# TC37XPD register map
Vendor: Infineon; Series: ATVMC; File version: 100
CPU: other r0p0, little endian, MPU, FPU, vendor SysTick, 4 interrupt priority bits
Registers are 32-bit, read-write, reset 0x0 unless marked. A register's access mark holds for its fields unless they carry their own. Offsets are from the block's base; [hi:lo] are bit positions; lines under a group give offsets from that group; {n}, {i} and the like mark numbered series.

## PMS (part 3 of 3)
Base 0xF0248000
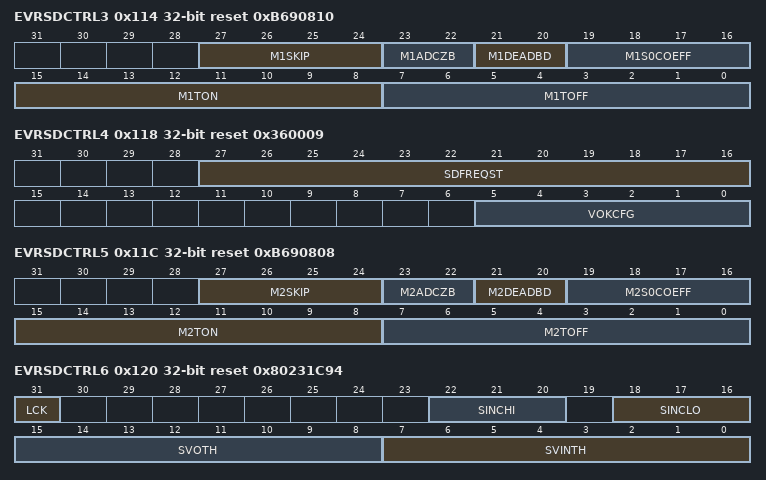
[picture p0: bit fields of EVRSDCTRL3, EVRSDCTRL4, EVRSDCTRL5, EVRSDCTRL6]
0x114 EVRSDCTRL3 reset 0xB690810 — EVRC SD Control Register 3 resetvalue={LVD Reset:0x0B690810,Cold PORST:0x0B690810,After SSW execution:0x0B690810}
  [27:24] M1SKIP — Skip Pulse Threshold m1skip thres i M1SKIP. This bitfield is disabled in LPM mode as PFM applied by control itself.
  [23:22] M1ADCZB — ADC Zero Bin m1fcfg adczb i M1ADCZB. This bitfield specifies the zero error bin during LP mode.
  [21:20] M1DEADBD — Dead Band m1s0 deadbd i M1DEADBD. This bitfield specifies the dead band to block the ADC ripple during LP mode.
  [19:16] M1S0COEFF — S0 coefficient m1s0 coeff i M1S0COEFF. This bitfield indicates the S0 coefficient during LP mode.
  [15:8] M1TON — Minimum On Time m1ton minton i M1TON. This bitfield configures the minimum on time within one period in 100MHz clock cycle periods during LP mode.
  [7:0] M1TOFF — Minimum Off Time m1toff mintof i M1TOFF. This bitfield configures the minimum off time within one period in 100MHz clock cycle periods during LP mode.
0x118 EVRSDCTRL4 reset 0x360009 — EVRC SD Control Register 4 resetvalue={LVD Reset:0x360009,Cold PORST:0x360009,After SSW execution:0x360009}
  [27:16] SDFREQST — Regulator Switching Frequency or Over sampling Factor m2osfl fact i m2osfh fact i SDFREQST. This bit field configures the EVRC regulator switching frequency during closed loop start up.The switching frequency is equal to 100 160 MHz SDFREQ value. SDFREQ represents the corresponding over sampling factor.
  [5:0] VOKCFG — Voltage OK Circuit Configuration vokcfg config i VOKCFG. t.b.d.
0x11C EVRSDCTRL5 reset 0xB690808 — EVRC SD Control Register 5 resetvalue={LVD Reset:0x0B690808,Cold PORST:0x0B690808,After SSW execution:0x0B690808}
  [27:24] M2SKIP — Skip Pulse Threshold m2skip thres i M2SKIP. This bitfield specifies the threshold to detect a skip pulse condition during closed loop operation. N channel MOSFET .
  [23:22] M2ADCZB — ADC Zero Bin m2fcfg adczb i M2ADCZB. This bitfield specifies the zero error bin during closed loop operation.
  [21:20] M2DEADBD — Dead Band m2s0 deadbd i M2DEADBD. This bitfield specifies the dead band to block the ADC ripple during closed loop operation.
  [19:16] M2S0COEFF — S0 coefficient m2s0 coeff i M2S0COEFF. This bitfield indicates the S0 coefficient during closed loop operation.
  [15:8] M2TON — Minimum On Time m2ton minton i M2TON. This bitfield configures the minimum on time within one period in 100MHz clock cycle periods during closed loop operation.
  [7:0] M2TOFF — Minimum Off Time m2toff mintof i M2TOFF. This bitfield configures the minimum off time within one period in 100MHz clock cycle periods during closed loop operation.
0x120 EVRSDCTRL6 access per field reset 0x80231C94 — EVRC SD Control Register 6 resetvalue={LVD Reset:0x080231C94,Cold PORST:0x080231C94,After SSW execution:0x080231C94}
  [31] LCK ro — Lock Status LCK. This bit indicates if the register can be updated with a new value or if the register is locked and a write action from the bus side has no effect. When EVRSDCTRL0.UP bit is set to 1 register is locked for shadow register update and LCK bit is set to 1. Once shadow register update is done the lock is released and LCK bit is set to 0.
  [22:20] SINCHI rw — Increment for high input voltage. sinc sinchi i SINCHI. This bitfield specifies the increment of the on time during open loop ramp up during startup. If Vin is below the threshold SVINTH SINCLO is taken as ramp up increment. if Vin is equal or above the threshold SVINTH SINCHI is taken as ramp up increment
  [18:16] SINCLO rw — Increment for low input voltage. sinc sinclo i SINCLO. This bitfield specifies the increment of the on time during open loop ramp up during startup. If Vin is below the threshold SVINTH SINCLO is taken as ramp up increment. if Vin is equal or above the threshold SVINTH SINCHI is taken as ramp up increment
  [15:8] SVOTH rw — Vout threshold to switch from open loop start up to closed loop mode. svoth thres i SVOTH. This bit field specifies the threshold to decide when to switch from open loop mode to closed loop mode during startup. If Vout is below the threshold open loop ramp up is executed. if Vout is equal or above the threshold closed loop PWM in start up configuration is executed. The threshold is compared to the low pass filtered FB ADC counter value without offset. The switch happens only in one direction during startup and the system does not switch back into start up mode even if threshold is crossed in other direction.
  [7:0] SVINTH rw — Vin threshold to switch between SINCLO or SINCHI. svinth thres i SVINTH. This bit field specifies the threshold to decide on the ramp up increment during startup. If Vin is below the threshold SINCLO is taken as ramp up increment else if Vin is equal or above the threshold SINCHI is taken as ramp up increment.The threshold is compared to the FF ADC counter value without offset.
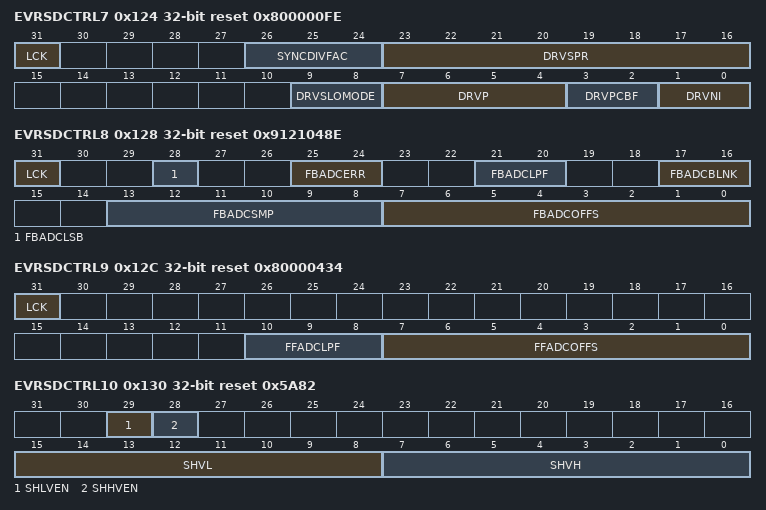
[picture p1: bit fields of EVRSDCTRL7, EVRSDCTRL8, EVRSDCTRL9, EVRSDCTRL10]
0x124 EVRSDCTRL7 access per field reset 0x800000FE — EVRC SD Control Register 7 resetvalue={LVD Reset:0x0800000FE,Cold PORST:0x0800000FE,After SSW execution:0x0800000FE}
  [31] LCK ro — Lock Status LCK. This bit indicates if the register can be updated with a new value or if the register is locked and a write action from the bus side has no effect. When EVRSDCTRL0.UP bit is set to 1 register is locked for shadow register update and LCK bit is set to 1. Once shadow register update is done the lock is released and LCK bit is set to 0.
  [26:24] SYNCDIVFAC rw — Switching frequency division factor for external synchronisation synco divfac i SYNCDIVFAC. This bit field defines the divider factor for the SMPS switching output to generate DCDCSYNCO output to synchronize external regulator to the internal EVRC regulator. The sigal is routed to pin if enabled via PMSWCR5.DCDCSYNCO bit. All other combinations are reserved.
  [23:16] DRVSPR rw — Spare bits drvspr x i DRVSPR
  [9:8] DRVSLOMODE rw — Switching Configuration drvslo mode i DRVSLOMODE. This bitfield configure the type of switching.
  [7:4] DRVP rw — P Driver Current drvp strgth i DRVP. Base drive current of the P channel MOSFET when driven with 3.3V 160 160 5V.
  [3:2] DRVPCBF rw — P Driver Current Boost Factor drvp strgth i DRVPCBF. Adjustable boost factor for the P driver current
  [1:0] DRVNI rw — Selection of N driver current DRVNI. Adjustable driver strength of the N driver current
0x128 EVRSDCTRL8 access per field reset 0x9121048E — EVRC SD Control Register 8 resetvalue={LVD Reset:0x09121048E,Cold PORST:0x09121048E,After SSW execution:0x09121048E}
  [31] LCK ro — Lock Status LCK. This bit indicates if the register can be updated with a new value or if the register is locked and a write action from the bus side has no effect. When EVRSDCTRL0.UP bit is set to 1 register is locked for shadow register update and LCK bit is set to 1. Once shadow register update is done the lock is released and LCK bit is set to 0.
  [28] FBADCLSB rw — FB ADC LSB for Error Computation fbadc3 lsb i FBADCLSB. This bitfield configures the LSB of the feedback ADC counter value used for the error computation.
  [25:24] FBADCERR rw — FB ADC Error LPF Coefficient fbadc3 lpferr i FBADCERR. This bitfield configures the coefficient of the Low Pass Filter of the output voltage error signal of the feedback ADC.
  [21:20] FBADCLPF rw — FB ADC Counter LPF Coefficient fbadc0 lpfcnt i FBADCLPF. This bit field configures the coefficient of the Low Pass Filter of the feedback ADC counter value measuring the core voltage. y 160 k 160 160 160 y 160 k 1 160 160 1 a 160 160 160 160 x 160 k 160 160 a 160 y 160 k is filter output x 160 k is ADC output a 160 160 1 160 160 2 160 160 LPF .If LPF 160 160 0 the filter output is the same as ADC output.
  [17:16] FBADCBLNK rw — FB ADC Blanked Samples Number fbadc0 blank i FBADCBLNK. This bitfield configures the number of feedback ADC samples that are blanked in case of a transition of the PWM drive output to minimise switching noise influence.
  [13:8] FBADCSMP rw — FB ADC Sampling period fbadc1 smpthr i FBADCSMP. This bitfield configures the sampling period in 100 MHz clock cycles for the feedback ADC measuring the core voltage.
  [7:0] FBADCOFFS rw — Feedback Converted Counter Value Offset fbadc2 offset i FBADCOFFS. This bitfield configures the offset of the converted counter value of the feedback ADC measuring the core voltage.
0x12C EVRSDCTRL9 access per field reset 0x80000434 — EVRC SD Control Register 9 resetvalue={LVD Reset:0x080000434,Cold PORST:0x080000434,After SSW execution:0x080000434}
  [31] LCK ro — Lock Status LCK. This bit indicates if the register can be updated with a new value or if the register is locked and a write action from the bus side has no effect. When EVRSDCTRL0.UP bit is set to 1 register is locked for shadow register update and LCK bit is set to 1. Once shadow register update is done the lock is released and LCK bit is set to 0.
  [10:8] FFADCLPF rw — FF ADC Counter LPF Coefficient ffadc0 lpfcnt i FFADCLPF. This bit field configures the coefficient of the Low Pass Filter of the feed forward ADC counter value measuring the input VEXT voltage. y 160 k 160 160 160 y 160 k 1 160 160 1 a 160 160 160 160 x 160 k 160 160 a 160 y 160 k is filter output x 160 k is ADC output a 160 160 1 160 160 2 160 160 LPF .If LPF 160 160 0 the filter output is the same as ADC output.
  [7:0] FFADCOFFS rw — Feed Forward Converted Counter Value Offset ffadc1 offset i FFADCOFFS. This bit field configures the offset of the converted counter value of the feed forward ADC measuring the input VEXT voltage.
0x130 EVRSDCTRL10 reset 0x5A82 — EVRC SD Control Register 10 resetvalue={LVD Reset:0x5A82,Cold PORST:0x5A82,After SSW execution:0x5A82}
  [29] SHLVEN — Short to Low Detection Enable shrtl0 shlven i SHLVEN
  [28] SHHVEN — Short to High Detection Enable shrth0 shhven i SHHVEN
  [15:8] SHVL — Short to Low Voltage Threshold shrtl1 shvl i SHVL. Low Voltage Threshold SDVOUTSEL 160 160 SHVL 160 x 160 5 160 mV . EVRC short to ground alarm has the nominal values of SHVL of 0.8V and tCSHLV of 3ms.
  [7:0] SHVH — Short to High Voltage Threshold shrth1 shvh i SHVH. High Voltage Threshold SDVOUTSEL 160 160 SHVH 160 x 160 5 160 mV . EVRC short to supply alarm has the nominal values of SHVH of 1.9V and tCSHHV of 3ms.
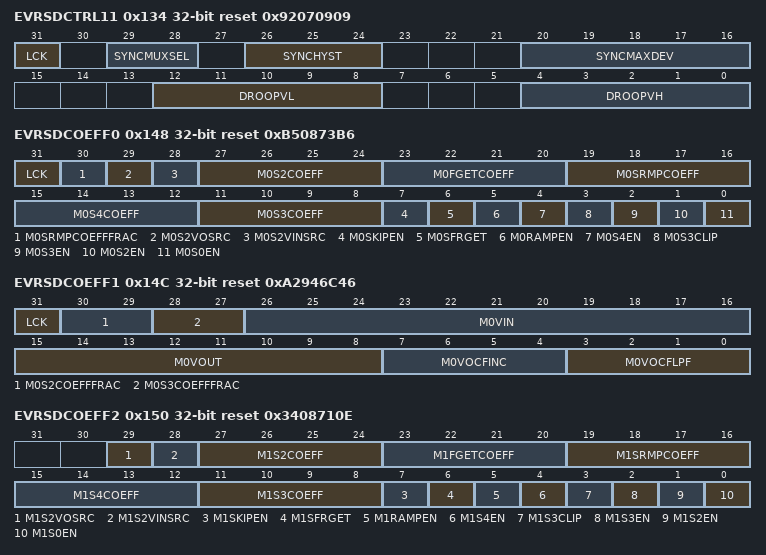
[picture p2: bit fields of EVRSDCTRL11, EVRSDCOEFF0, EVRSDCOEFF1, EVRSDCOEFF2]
0x134 EVRSDCTRL11 access per field reset 0x92070909 — EVRC SD Control Register 11 resetvalue={LVD Reset:0x092070909,Cold PORST:0x092070909,After SSW execution:0x092070909}
  [31] LCK ro — Lock Status LCK. This bit indicates if the register can be updated with a new value or if the register is locked and a write action from the bus side has no effect. When EVRSDCTRL0.UP bit is set to 1 register is locked for shadow register update and LCK bit is set to 1. Once shadow register update is done the lock is released and LCK bit is set to 0.
  [29:28] SYNCMUXSEL rw — Synchronisation Input Multiplexer SYNCMUXSEL. This bitfield selects synchronisation input either from CCU6 or GTM inputs to be forwarded to EVRC SMPS regulator.
  [26:24] SYNCHYST rw — Lock Unlock Hysteresis Window synci0 hyst i SYNCHYST. This bitfield defines the hysteresis window for synchronization locking and unlocking. For locking EVRSDCTRL11.SYNCHYST has to be chosen to be lower or equal to the value of EVRSDCTRL11.SYNCMAXDEV and unequal to zero. The limit is applied to the period counter running at 100 MHz. Upper unlock condition SDFREQ SYNCMAXDEV Upper lock condition SDFREQ SYNCMAXDEV SYNCHYST Lower unlock condition SDFREQ SYNCMAXDEV Lower lock condition SDFREQ SYNCMAXDEV SYNCHYST SYNCHYST round d 160 f HYST SDFREQ 177 SYNCMAXDEV 2 d 160 f HYST SDFREQ 177 SYNCMAXDEV 100 MHz
  [20:16] SYNCMAXDEV rw — Maximum Deviation of the Synchronization Input Frequency synci1 maxdev i SYNCMAXDEV. This bitfield defines the maximum allowed frequency deviation of the synchronization input signal frequency from the programmed nominal DCDC switching frequency EVRSDCTRL0.SDFREQ . For locking EVRSDCTRL11.SYNCMAXDEV has to be chosen to be greater or equal to the value of EVRSDCTRL11.SYNCHYST and unequal to zero. Violation of limit leads to loss of synchronization.The frequency window is defined as follows d 160 f MAXDEV 160 100 MHz 2 SYNCMAXDEV SDFREQ 2 SYNCMAXDEV 2 SYNCMAXDEV 160 round 100 MHz d 160 f MAXDEV sqrt 100 MHz d 160 f MAXDEV 2 SDFREQ 2
  [12:8] DROOPVL rw — Low VDD Limit for Droop request droopvl thres i DROOPVL. This bitfield defines the VDD low voltage limit below which a negative droop request on VDD voltage shall be ignored. VDD Droop Low Limit 712.5 mV LSB SDVOUTSEL SDVOUTTRIM DROOPVL LSB 5 mV
  [4:0] DROOPVH rw — High VDD Limit for Droop request droopvh thres i DROOPVH. This bitfield defines the VDD high voltage limit above which a positive droop request on VDD voltage shall be ignored. VDD Droop High Limit 712.5 mV LSB SDVOUTSEL SDVOUTTRIM DROOPVH LSB 5 mV
0x148 EVRSDCOEFF0 access per field reset 0xB50873B6 — EVRC SD Coefficient Register 0 resetvalue={LVD Reset:0x0B50873B6,Cold PORST:0x0B50873B6,After SSW execution:0x0B50873B6}
  [31] LCK ro — Lock Status LCK. This bit indicates if the register can be updated with a new value or if the register is locked and a write action from the bus side has no effect. When EVRSDCTRL0.UP bit is set to 1 register is locked for shadow register update and LCK bit is set to 1. Once shadow register update is done the lock is released and LCK bit is set to 0.
  [30] M0SRMPCOEFFFRAC rw — S Ramp Fractional Coefficient. This bitfield specifies the S Ramp fractional coefficient.
  [29] M0S2VOSRC rw — S2 Vout Source m0s2 vosrc i M0S2VOSRC. This bitfield specifies the source of the output voltage used for the inductor current reconstruction.
  [28] M0S2VINSRC rw — S2 Vin Source m0s2 vinsrc i M0S2VINSRC. This bitfield specifies the source of the input voltage used for the inductor current reconstruction.
  [27:24] M0S2COEFF rw — S2 Coefficient m0s2 coeff i M0S2COEFF. Inductor current reconstruction coefficient.
  [23:20] M0FGETCOEFF rw — S2 Forgetting Factor m0fget coeff i M0FGETCOEFF. This bitfield specifies the forgetting factor for compensation of parasitic effects.
  [19:16] M0SRMPCOEFF rw — S Ramp Coefficient m0srmp coeff i M0SRMPCOEFF. Configuration register of S Ramp artificial ramp coefficient.
  [15:12] M0S4COEFF rw — S4 Coefficient m0s4 coeff i M0S4COEFF. Configuration register of S4 double integrator coefficient.
  [11:8] M0S3COEFF rw — S3 Coefficient m0s3 coeff i M0S3COEFF. Configuration register of S3 integrator coefficient.
  [7] M0SKIPEN rw — Skip Enable m0en skipen i M0SKIPEN. This bitfield enables the skip pulse logic.
  [6] M0SFRGET rw — SFRGET m0en sfrget i M0SFRGET. This bitfield enables the compensation of parasitic effects in the inductor current reconstruction.
  [5] M0RAMPEN rw — Ramp Enable m0en rampen i M0RAMPEN. This bitfield enables the artificial ramp in order to avoid instabilities at high duty cycles.
  [4] M0S4EN rw — S4 Enable m0en s4en i M0S4EN. This bitfield enables the double integrator branch.
  [3] M0S3CLIP rw — S3 Clip m0en s3clip i M0S3CLIP. This bitfield specifies the clipping of the integrator state to negative values.
  [2] M0S3EN rw — S3 Enable m0en s3en i M0S3EN. This bitfield enables the integrator.
  [1] M0S2EN rw — S2 Enable m0en s2en i M0S2EN. This bitfield enables the digital reconstruction of the inductor current.
  [0] M0S0EN rw — S0 Enable m0en s0en i M0S0EN. This bitfield enables the fast forward error term.
0x14C EVRSDCOEFF1 access per field reset 0xA2946C46 — EVRC SD Coefficient Register 1 resetvalue={LVD Reset:0x0A2946C46,Cold PORST:0x0A2946C46,After SSW execution:0x0A2946C46}
  [31] LCK ro — Lock Status LCK. This bit indicates if the register can be updated with a new value or if the register is locked and a write action from the bus side has no effect. When EVRSDCTRL0.UP bit is set to 1 register is locked for shadow register update and LCK bit is set to 1. Once shadow register update is done the lock is released and LCK bit is set to 0.
  [30:29] M0S2COEFFFRAC rw — S2 Fractional Coefficient. This bitfield specifies the S2 fractional coefficient of the inductor current reconstruction coefficient. 00 no fractional coefficient used 01 ... fractional coefficient 1 4 used S2 0.25 10 ... fractional coefficient 1 2 used S2 0.5 11 ... fractional coefficient 3 4 used S2 0.75
  [28:27] M0S3COEFFFRAC rw — S3 Fractional Coefficient. This bitfield specifies the S3 fractional integrator coefficient. 00 no fractional coefficient used 01 ... fractional coefficient 1 4 used S3 0.25 10 ... fractional coefficient 1 2 used S3 0.5 11 ... fractional coefficient 3 4 used S3 0.75
  [26:16] M0VIN rw — Digital representation of the input voltage m0vinh vin i m0vinl vin i M0VIN. This bitfield is used for the inductor current reconstruction instead of the FFADC value. Absolute value including ADC offset.
  [15:8] M0VOUT rw — Digital representation of the target voltage m0vo lb i M0VOUT. This bitfield can be used for the inductor current reconstruction instead of the FBADC value.
  [7:4] M0VOCFINC rw — Output Voltage Ramp Coefficient m0vocf inc i M0VOCFINC. This bitfield reflects increment for the output voltage ramp used in the inductor current reconstruction. Step applied to ramp 2 160 160 M0VOCFINC.
  [3:0] M0VOCFLPF rw — LPF Coefficient m0vocf lpf i M0VOCFLPF. This bitfield reflects LPF coefficient used in the LPF applied to the FB ADC counter value or the programmed register value. y 160 k 160 160 160 y 160 k 1 160 160 1 a 160 160 160 160 x 160 k 160 160 a 160 y 160 k is filter output x 160 k is ADC output a 160 160 1 160 160 2 160 160 LPF .If LPF 160 160 0 the filter output is the same as ADC output.
0x150 EVRSDCOEFF2 reset 0x3408710E — EVRC SD Coefficient Register 2 resetvalue={LVD Reset:0x3408710E,Cold PORST:0x3408710E,After SSW execution:0x3408710E}
  [29] M1S2VOSRC — S2 Vout Source m1s2 vosrc i M1S2VOSRC. This bitfield specifies the source of the output voltage used for the inductor current reconstruction.
  [28] M1S2VINSRC — S2 Vin Source m1s2 vinsrc i M1S2VINSRC. This bitfield specifies the source of the input voltage used for the inductor current reconstruction.
  [27:24] M1S2COEFF — S2 Coefficient m1s2 coeff i M1S2COEFF. Inductor current reconstruction coefficient.
  [23:20] M1FGETCOEFF — S2 Forgetting Factor m1fget coeff i M1FGETCOEFF. This bitfield specifies the forgetting factor for compensation of parasitic effects.
  [19:16] M1SRMPCOEFF — S Ramp Coefficient m1srmp coeff i M1SRMPCOEFF. Configuration register of S Ramp artificial ramp coefficient.
  [15:12] M1S4COEFF — S4 Coefficient m1s4 coeff i M1S4COEFF. Configuration register of S4 double integrator coefficient.
  [11:8] M1S3COEFF — S3 Coefficient m1s3 coeff i M1S3COEFF. Configuration register of S3 integrator coefficient.
  [7] M1SKIPEN — Skip Enable m1en skipen i M1SKIPEN. This bitfield enables the skip pulse logic.
  [6] M1SFRGET — SFRGET m1en sfrget i M1SFRGET. This bitfield enables the compensation of parasitic effects in the inductor current reconstruction.
  [5] M1RAMPEN — Ramp Enable m1en rampen i M1RAMPEN. This bitfield enables the artificial ramp in order to avoid instabilities at high duty cycles.
  [4] M1S4EN — S4 Enable m1en s4en i M1S4EN. This bitfield enables the double integrator branch.
  [3] M1S3CLIP — S3 Clip m1en s3clip i M1S3CLIP. This bitfield specifies the clipping of the integrator state to negative values.
  [2] M1S3EN — S3 Enable m1en s3en i M1S3EN. This bitfield enables the integrator.
  [1] M1S2EN — S2 Enable m1en s2en i M1S2EN. This bitfield enables the digital reconstruction of the inductor current.
  [0] M1S0EN — S0 Enable m1en s0en i M1S0EN. This bitfield enables the fast forward error term.
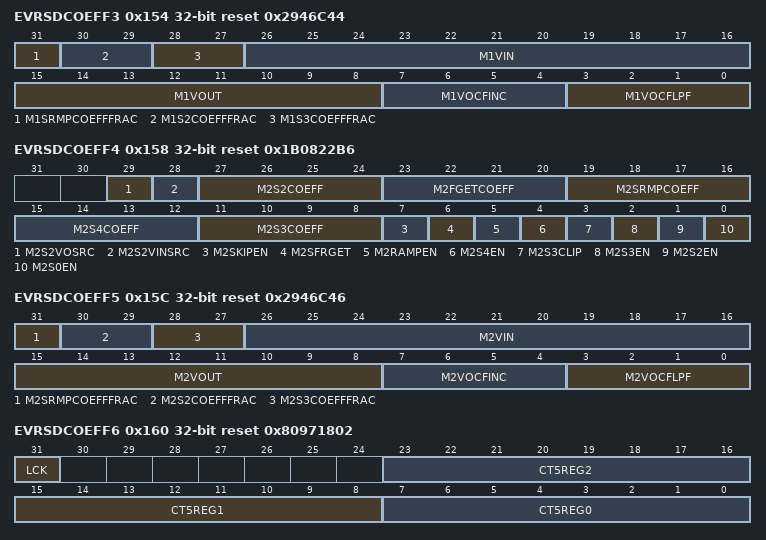
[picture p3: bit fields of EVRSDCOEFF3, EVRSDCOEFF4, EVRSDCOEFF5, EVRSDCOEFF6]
0x154 EVRSDCOEFF3 reset 0x2946C44 — EVRC SD Coefficient Register 3 resetvalue={LVD Reset:0x2946C44,Cold PORST:0x2946C44,After SSW execution:0x2946C44}
  [31] M1SRMPCOEFFFRAC — S Ramp Fractional Coefficient. This bitfield specifies the S Ramp fractional coefficient.
  [30:29] M1S2COEFFFRAC — S2 Fractional Coefficient. This bitfield specifies the S2 fractional coefficient of the inductor current reconstruction coefficient. 00 no fractional coefficient used 01 ... fractional coefficient 1 4 used S2 0.25 10 ... fractional coefficient 1 2 used S2 0.5 11 ... fractional coefficient 3 4 used S2 0.75
  [28:27] M1S3COEFFFRAC — S3 Fractional Coefficient. This bitfield specifies the S3 fractional integrator coefficient. 00 no fractional coefficient used 01 ... fractional coefficient 1 4 used S3 0.25 10 ... fractional coefficient 1 2 used S3 0.5 11 ... fractional coefficient 3 4 used S3 0.75
  [26:16] M1VIN — Digital representation of the input voltage m1vinh vin i m1vinl vin i M1VIN. This bitfield can be used for the inductor current reconstruction instead of the FFADC value. Absolute value including ADC offset.
  [15:8] M1VOUT — Digital representation of the target voltage m1vo lb i M1VOUT. This bitfield can be used for the inductor current reconstruction instead of the FBADC value.
  [7:4] M1VOCFINC — Output Voltage Ramp Coefficient m1vocf inc i M1VOCFINC. This bitfield reflects increment for the output voltage ramp used in the inductor current reconstruction. Step applied to ramp 2 160 160 M1VOCFINC.
  [3:0] M1VOCFLPF — LPF Coefficient m1vocf lpf i M1VOCFLPF. This bitfield reflects LPF coefficient used in the LPF applied to the FB ADC counter value or the programmed register value. y 160 k 160 160 160 y 160 k 1 160 160 1 a 160 160 160 160 x 160 k 160 160 a 160 y 160 k is filter output x 160 k is ADC output a 160 160 1 160 160 2 160 160 LPF .If LPF 160 160 0 the filter output is the same as ADC output.
0x158 EVRSDCOEFF4 reset 0x1B0822B6 — EVRC SD Coefficient Register 4 resetvalue={LVD Reset:0x1B0822B6,Cold PORST:0x1B0822B6,After SSW execution:0x1B0822B6}
  [29] M2S2VOSRC — S2 Vout Source m2s2 vosrc i M2S2VOSRC. This bitfield specifies the source of the output voltage used for the inductor current reconstruction.
  [28] M2S2VINSRC — S2 Vin Source m2s2 vinsrc i M2S2VINSRC. This bitfield specifies the source of the input voltage used for the inductor current reconstruction.
  [27:24] M2S2COEFF — S2 Coefficient m2s2 coeff i M2S2COEFF. Inductor current reconstruction coefficient.
  [23:20] M2FGETCOEFF — S2 Forgetting Factor m2fget coeff i M2FGETCOEFF. This bitfield specifies the forgetting factor for compensation of parasitic effects.
  [19:16] M2SRMPCOEFF — S Ramp Coefficient m2srmp coeff i M2SRMPCOEFF. Configuration register of S Ramp artificial ramp coefficient.
  [15:12] M2S4COEFF — S4 Coefficient m2s4 coeff i M2S4COEFF. Configuration register of S4 double integrator coefficient.
  [11:8] M2S3COEFF — S3 Coefficient m2s3 coeff i M2S3COEFF. Configuration register of S3 integrator coefficient.
  [7] M2SKIPEN — Skip Enable m2en skipen i M2SKIPEN. This bitfield enables the skip pulse logic.
  [6] M2SFRGET — SFRGET m2en sfrget i M2SFRGET. This bitfield enables the compensation of parasitic effects in the inductor current reconstruction.
  [5] M2RAMPEN — Ramp Enable m2en rampen i M2RAMPEN. This bitfield enables the artificial ramp in order to avoid instabilities at high duty cycles.
  [4] M2S4EN — S4 Enable m2en s4en i M2S4EN. This bitfield enables the double integrator branch.
  [3] M2S3CLIP — S3 Clip m2en s3clip i M2S3CLIP. This bitfield specifies the clipping of the integrator state to negative values.
  [2] M2S3EN — S3 Enable m2en s3en i M2S3EN. This bitfield enables the integrator.
  [1] M2S2EN — S2 Enable m2en s2en i M2S2EN. This bitfield enables the digital reconstruction of the inductor current.
  [0] M2S0EN — S0 Enable m2en s0en i M2S0EN. This bitfield enables the fast forward error term.
0x15C EVRSDCOEFF5 reset 0x2946C46 — EVRC SD Coefficient Register 5 resetvalue={LVD Reset:0x2946C46,Cold PORST:0x2946C46,After SSW execution:0x2946C46}
  [31] M2SRMPCOEFFFRAC — S Ramp Fractional Coefficient. This bitfield specifies the S Ramp fractional coefficient.
  [30:29] M2S2COEFFFRAC — S2 Fractional Coefficient. This bitfield specifies the S2 fractional coefficient of the inductor current reconstruction coefficient. 00 no fractional coefficient used 01 ... fractional coefficient 1 4 used S2 0.25 10 ... fractional coefficient 1 2 used S2 0.5 11 ... fractional coefficient 3 4 used S2 0.75
  [28:27] M2S3COEFFFRAC — S3 Fractional Coefficient. This bitfield specifies the S3 fractional integrator coefficient. 00 no fractional coefficient used 01 ... fractional coefficient 1 4 used S3 0.25 10 ... fractional coefficient 1 2 used S3 0.5 11 ... fractional coefficient 3 4 used S3 0.75
  [26:16] M2VIN — Digital representation of the input voltage m2vinh vin i m2vinl vin i M2VIN. This bitfield can be used for the inductor current reconstruction instead of the FFADC value. Absolute value including ADC offset.
  [15:8] M2VOUT — Digital representation of the target voltage m2vo lb i M2VOUT. This bitfield can be used for the inductor current reconstruction instead of the FBADC value.
  [7:4] M2VOCFINC — Output Voltage Ramp Coefficient m2vocf inc i M2VOCFINC. This bitfield reflects the increment for the output voltage ramp used in the inductor current reconstruction. Step applied to ramp 2 160 160 M2VOCFINC.
  [3:0] M2VOCFLPF — LPF Coefficient m2vocf lpf i M2VOCFLPF. This bitfield reflects LPF coefficient used in the LPF applied to the FB ADC counter value or the programmed register value. y 160 k 160 160 160 y 160 k 1 160 160 1 a 160 160 160 160 x 160 k 160 160 a 160 y 160 k is filter output x 160 k is ADC output a 160 160 1 160 160 2 160 160 LPF .If LPF 160 160 0 the filter output is the same as ADC output.
0x160 EVRSDCOEFF6 access per field reset 0x80971802 — EVRC SD Coefficient Register 6 resetvalue={LVD Reset:0x080971802,Cold PORST:0x080971802,After SSW execution:0x080971802}
  [31] LCK ro — Lock Status LCK. This bit indicates if the register can be updated with a new value or if the register is locked and a write action from the bus side has no effect. When EVRSDCTRL0.UP bit is set to 1 register is locked for shadow register update and LCK bit is set to 1. Once shadow register update is done the lock is released and LCK bit is set to 0.
  [23:16] CT5REG2 rw — Commutation trimming drv5v2 trim i CT5REG2. Trimming of the commutation parameters of the external driver 5V .
  [15:8] CT5REG1 rw — Commutation trimming drv5v1 trim i CT5REG1. Trimming of the commutation parameters of the external driver 5V .
  [7:0] CT5REG0 rw — Commutation trimming and Slope Control drv5v0 trim i CT5REG0. Trimming of the commutation parameters of the external driver 5V .
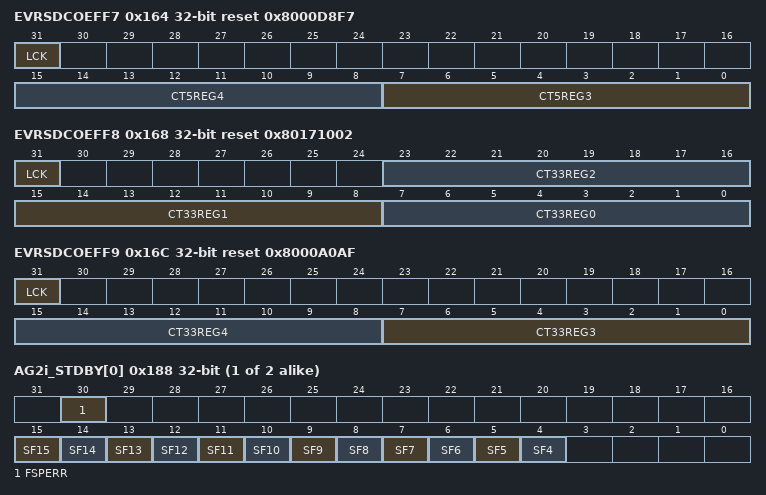
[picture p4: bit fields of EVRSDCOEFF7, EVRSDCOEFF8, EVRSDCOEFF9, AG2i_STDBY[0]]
0x164 EVRSDCOEFF7 access per field reset 0x8000D8F7 — EVRC SD Coefficient Register 7 resetvalue={LVD Reset:0x08000D8F7,Cold PORST:0x08000D8F7,After SSW execution:0x08000D8F7}
  [31] LCK ro — Lock Status LCK. This bit indicates if the register can be updated with a new value or if the register is locked and a write action from the bus side has no effect. When EVRSDCTRL0.UP bit is set to 1 register is locked for shadow register update and LCK bit is set to 1. Once shadow register update is done the lock is released and LCK bit is set to 0.
  [15:8] CT5REG4 rw — Commutation trimming drv5v4 trim i CT5REG4. Trimming of the commutation parameters of the external driver 5V .
  [7:0] CT5REG3 rw — Commutation trimming drv5v3 trim i CT5REG3. Trimming of the commutation parameters of the external driver 5V .
0x168 EVRSDCOEFF8 access per field reset 0x80171002 — EVRC SD Coefficient Register 8 resetvalue={LVD Reset:0x080171002,Cold PORST:0x080171002,After SSW execution:0x080171002}
  [31] LCK ro — Lock Status LCK. This bit indicates if the register can be updated with a new value or if the register is locked and a write action from the bus side has no effect. When EVRSDCTRL0.UP bit is set to 1 register is locked for shadow register update and LCK bit is set to 1. Once shadow register update is done the lock is released and LCK bit is set to 0.
  [23:16] CT33REG2 rw — Commutation trimming drv3v2 trim i CT33REG2. Trimming of the commutation parameters of the external driver 3.3V .
  [15:8] CT33REG1 rw — Commutation trimming drv3v1 trim i CT33REG1. Trimming of the commutation parameters of the external driver 3.3V .
  [7:0] CT33REG0 rw — Commutation trimming drv3v0 trim i CT33REG0. Trimming of the commutation parameters of the external driver 3.3V .
0x16C EVRSDCOEFF9 access per field reset 0x8000A0AF — EVRC SD Coefficient Register 9 resetvalue={LVD Reset:0x08000A0AF,Cold PORST:0x08000A0AF,After SSW execution:0x08000A0AF}
  [31] LCK ro — Lock Status LCK. This bit indicates if the register can be updated with a new value or if the register is locked and a write action from the bus side has no effect. When EVRSDCTRL0.UP bit is set to 1 register is locked for shadow register update and LCK bit is set to 1. Once shadow register update is done the lock is released and LCK bit is set to 0.
  [15:8] CT33REG4 rw — Commutation trimming drv3v4 trim i CT33REG4. Trimming of the commutation parameters of the external driver 3.3V .
  [7:0] CT33REG3 rw — Commutation trimming drv3v3 trim i CT33REG3. Trimming of the commutation parameters of the external driver 3.3V .
{0x188+4i} AG2i_STDBY[{i}] (i=0..1) — Alarm Status Register resetvalue={LVD Reset:0x0}
  [30] FSPERR — Error Pin Fault State Status Bit FSPERR. The bit indicates that Error pin was set into fault state by the SMU stdby. Reset by setting to 1. If the Error Pins were set in fault state by the SMU stdby reseting this bit sets the Error Pins back in fault free state
  [n] SF{n} (n=4..15) — Status flag for alarm 16 belonging to alarm group i. SF16
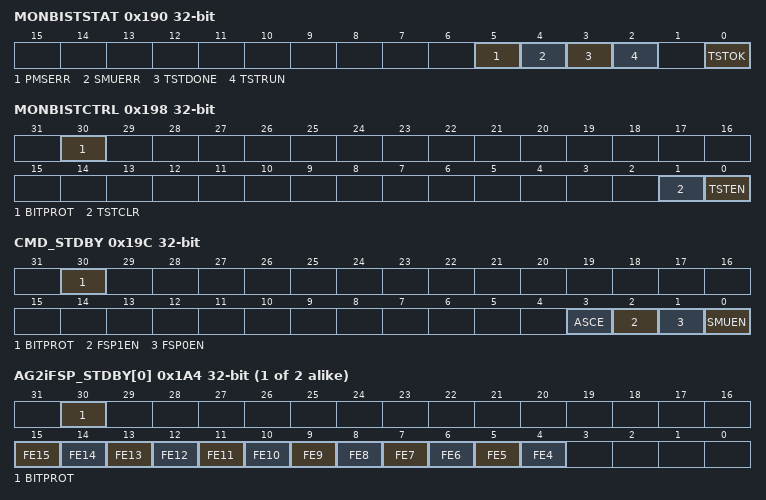
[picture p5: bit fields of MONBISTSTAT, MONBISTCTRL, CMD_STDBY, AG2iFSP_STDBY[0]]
0x190 MONBISTSTAT ro — SMU stdby BIST Status Register resetvalue={LVD Reset:0x0,Warm PORST:0x0}
  [5] PMSERR — Error found in PMS SARADC by SMU stdby BIST. This status bit indicates that SMU stdby BIST found an error in the PMS SARADC.
  [4] SMUERR — Error found in SMU stdby found by SMU stdby BIST. This status bit indicates that the MONBIST test found an error in the SMU stdby.
  [3] TSTDONE — SMU stdby BIST done bit TSTDONE. The status bit indicates that MONBIST test is completed.
  [2] TSTRUN — SMU stdby BIST run bit TSTRUN. The status bit indicates that MONBIST test is ongoing.
  [0] TSTOK — SMU stdby BIST ok bit TSTOK. This status bit indicates that MONBIST test was successful and the result is as expected.
0x198 MONBISTCTRL access per field — SMU stdby BIST Control Register resetvalue={LVD Reset:0x0,Warm PORST:0x0}
  [30] BITPROT wo — Bit Protection TSTEN BITPROT. Setting this bit enables that bit TSTEN can be changed in this write operation. This bit is read as zero.
  [1] TSTCLR wo — SMU stdby BIST flag clear TSTCLR. Setting this bit enables the clearing of the bitfields TSTOK TSTDONE TSTRUN SMUERR and PMSERR of register MONBISTSTAT.
  [0] TSTEN rw — SMU stdby alarm BIST enable TSTEN. If SMUEN in the CMD stdby register is set to 1 setting the TSTEN bit triggers SMU stdby BIST tests to test the alarm path and PMS components. This bit can only be changed if bit BITPROT is set in parallel. This bit is cleared by hardware at the end of the SMU stdby BIST operation.
0x19C CMD_STDBY access per field — SMU stdby Command Register resetvalue={LVD Reset:0x0,Warm PORST:0x0}
  [30] BITPROT wo — CMD STDBY register bits protection. Setting this bit enables that bits SMUEN FSP0EN FSP1EN or and ASCE can be changed in this write operation. This bit is read as zero.
  [3] ASCE rw — SMU stdby alarm status clear enable ASCE. This bit controls if a status flag set in an AGx register upon detection of the alarm event can be cleared by software or not. When ASCE is enabled software shall write a 1 to bit position in AGx to clear the bit W1C . When a W1C action takes place the ASCE bit is automatically cleared to 0 by hardware and software shall set the ASCE bit again.
  [2] FSP1EN rw — SMU stdby FSP1 Error pin enable FSP1EN. This bit enables SMU stdby Error pin function to be able set P33.10 to fault state.
  [1] FSP0EN rw — SMU stdby FSP0 Error pin enable FSP0EN. This bit enables SMU stdby Error pin function to be able set P33.8 to fault state.
  [0] SMUEN rw — SMU stdby Module Enable SMUEN. This bit enables SMU stdby to issue a FSP reaction when an alarm is received. Also SMUEN needs to be set to enter the SMU stdby BIST mode.
{0x1A4+4i} AG2iFSP_STDBY[{i}] (i=0..1) access per field — SMU stdby FSP Configuration Register resetvalue={LVD Reset:0x0,Warm PORST:0x0}
  [30] BITPROT wo — AG2iFSP STDBY register bits protection. Setting this bit enables that bits FE z can be changed in this write operation. This bit is read as zero.
  [n] FE{n} rw (n=4..15) — Fault signaling configuration flag for alarm 16 belonging to alarm group i. FE16
0x1C0 DTSSTAT ro — Die Temperature Sensor Status Register resetvalue={LVD Reset:0x0,Cold PORST:0x0}
  [11:0] RESULT — Result of the DTS Measurement RESULT. This bit field shows the result of the DTS measurement. The value given is directly related to the die temperature and can be evaluated using the following formula. T 176 C RESULT Gnom 273.15 T 176 K RESULT G nom RESULT G nom T 176 C 273.15 G nom T 176 K G nom 7.505
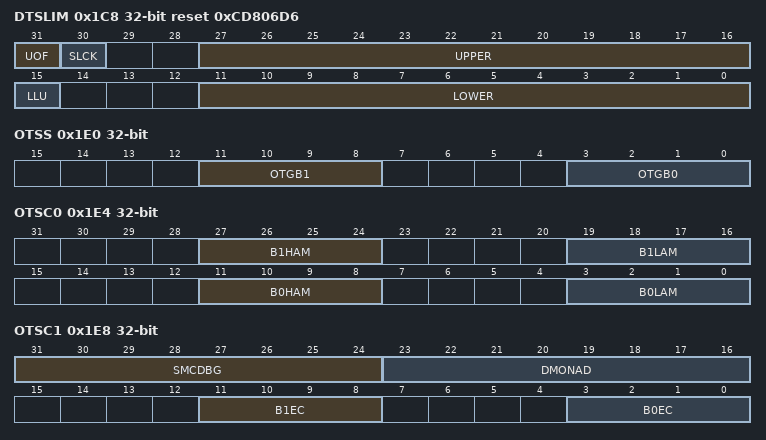
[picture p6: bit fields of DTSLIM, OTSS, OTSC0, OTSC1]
0x1C8 DTSLIM reset 0xCD806D6 — Die Temperature Sensor Limit Register resetvalue={LVD Reset:0x0CD806D6,Cold PORST:0x0CD806D6}
  [31] UOF — Upper Limit Overflow UOF. When this bit is set a HSM temperature overflow trigger is generated. When this bit is set the related SMU DTS alarm trigger is generated. This bit has to be written with zero in order to clear it. Writing a one has no effect. This bit is set when a DTS measurement is finished and the result is exceeding the upper limit i.e. DTSLIM.UPPER .
  [30] SLCK — HSM Security Lock SLCK. If this bit is set all other bits in this register can no longer be written. Write requests to other bits when SLCK is set will trigger an SLCK access error alarm.This bit can not by cleared by software. SLCK bit can only be set by an access from the HSM master TAG 160 160 000011 B . A set operation performed by any other master or software is ignored and the bit is kept as cleared.
  [27:16] UPPER — Upper Limit UPPER. This bit field defines the upper limit of the DTS temperature check. The DTS measurement result is compared against this value and if the measurement result is greater than or equal to the configured UPPER bitfield value flag UOF is set.
  [15] LLU — Lower Limit Underflow LLU. When this bit is set a HSM temperature underflow trigger is generated. When this bit is set the related SMU DTS alarm trigger is generated. This bit has to be written with zero in order to clear it. Writing a one has no effect. This bit is set when a DTS measurement is finished and the result is below the lower limit i.e. DTSLIM.LOWER .
  [11:0] LOWER — Lower Limit LOWER. This bit field defines the lower limit of the DTS temperature check. The DTS measurement result is compared against this value and if the measurement result is less than or equal to the configured LOWER bitfield value flag LLU is set.
0x1E0 OTSS — OCDS Trigger Set Select Register resetvalue={LVD Reset:0x0,Debug Reset:0x0}
  [11:8] OTGB1 — Trigger Set for OTGB1 OTGB1
  [3:0] OTGB0 — Trigger Set for OTGB0 OTGB0
0x1E4 OTSC0 — OCDS Trigger Set Control 0 Register resetvalue={LVD Reset:0x0,Debug Reset:0x0}
  [27:24] B1HAM — OTGB1 TS16 ADCMON High Byte B1HAM
  [19:16] B1LAM — OTGB1 TS16 ADCMON Low Byte B1LAM
  [11:8] B0HAM — OTGB0 TS16 ADCMON High Byte B0HAM
  [3:0] B0LAM — OTGB0 TS16 ADCMON Low Byte B0LAM
0x1E8 OTSC1 — OCDS Trigger Set Control 1 Register resetvalue={LVD Reset:0x0,Debug Reset:0x0}
  [31:24] SMCDBG — OTGB0 TS16 EVRCON SMCDBG SMCDBG. Reserved for future extensions.
  [23:16] DMONAD — OTGB0 TS16 EVRCON DMONAD DMONAD. The multiplexer signal selection documented in DMONAD coding table.
  [11:8] B1EC — OTGB1 TS16 EVRCON B1EC
  [3:0] B0EC — OTGB0 TS16 EVRCON B0EC
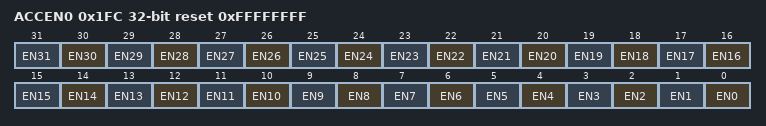
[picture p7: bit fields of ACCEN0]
0x1FC ACCEN0 reset 0xFFFFFFFF — Access Enable Register 0 resetvalue={Application Reset:0x0FFFFFFFF}
  [n] EN{n} (n=0..31) — Access Enable for Master TAG ID 31 EN31. This bit enables write access to the PMS kernel addresses for transactions with the Master TAG ID n
